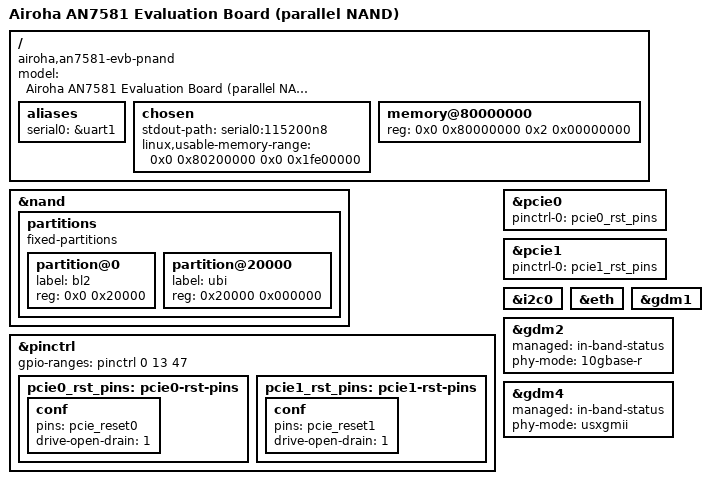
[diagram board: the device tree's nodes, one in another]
// SPDX-License-Identifier: (GPL-2.0-only OR BSD-2-Clause)
/dts-v1/;

#include "an7581.dtsi"

/ {
	model = "Airoha AN7581 Evaluation Board (parallel NAND)";
	compatible = "airoha,an7581-evb-pnand",
		     "airoha,an7581",
		     "airoha,en7581";

	aliases {
		serial0 = &uart1;
	};

	chosen {
		stdout-path = "serial0:115200n8";
		linux,usable-memory-range = <0x0 0x80200000 0x0 0x1fe00000>;
	};

	memory@80000000 {
		device_type = "memory";
		reg = <0x0 0x80000000 0x2 0x00000000>;
	};
};

/*
 * The EVB wires a raw NAND device to the NFI block instead of the SPI-NAND
 * part, so the parallel interface is used.  &snfi keeps its default disabled
 * state from an7581.dtsi: both nodes drive the same NFI block and only one of
 * them may be enabled.
 */
&nand {
	status = "okay";

	partitions {
		compatible = "fixed-partitions";
		#address-cells = <1>;
		#size-cells = <1>;

		partition@0 {
			label = "bl2";
			reg = <0x0 0x20000>;
		};

		partition@20000 {
			label = "ubi";
			reg = <0x20000 0x000000>;
		};
	};
};

&pinctrl {
	gpio-ranges = <&pinctrl 0 13 47>;

	pcie0_rst_pins: pcie0-rst-pins {
		conf {
			pins = "pcie_reset0";
			drive-open-drain = <1>;
		};
	};

	pcie1_rst_pins: pcie1-rst-pins {
		conf {
			pins = "pcie_reset1";
			drive-open-drain = <1>;
		};
	};
};

&pcie0 {
	pinctrl-names = "default";
	pinctrl-0 = <&pcie0_rst_pins>;
	status = "okay";
};

&pcie1 {
	pinctrl-names = "default";
	pinctrl-0 = <&pcie1_rst_pins>;
	status = "okay";
};

&i2c0 {
	status = "okay";
};

&eth {
	status = "okay";
};

&gdm1 {
	status = "okay";
};

&gdm2 {
	status = "okay";

	managed = "in-band-status";
	phy-mode = "10gbase-r";
};

&gdm4 {
	status = "okay";

	managed = "in-band-status";
	phy-mode = "usxgmii";
};
